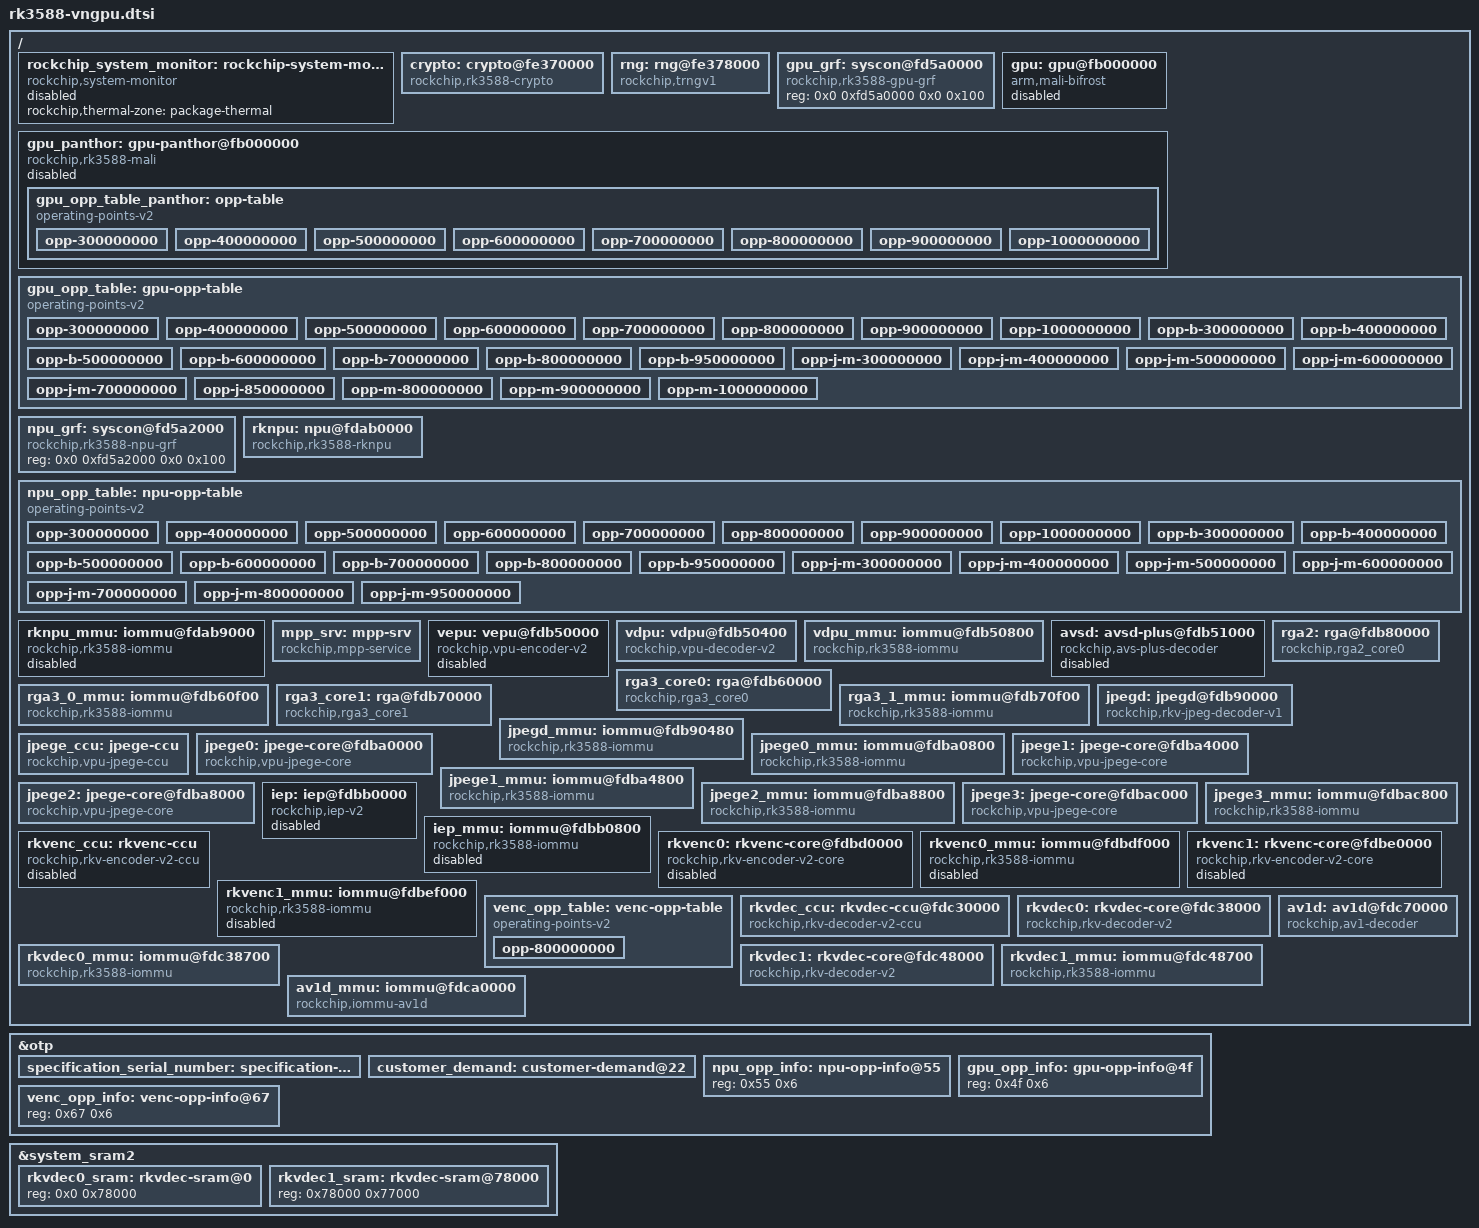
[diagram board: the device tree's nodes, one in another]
/*
 * Copyright (c) 2021 Rockchip Electronics Co., Ltd.
 * Copyright (c) 2025 jjm2473 <jjm2473@gmail.com>
 */

/delete-node/ &gpu;
/delete-node/ &gpu_opp_table;
/delete-node/ &av1d;

/{
	rockchip_system_monitor: rockchip-system-monitor {
		compatible = "rockchip,system-monitor";

		rockchip,thermal-zone = "package-thermal";
		status = "disabled";
	};

	crypto: crypto@fe370000 {
		compatible = "rockchip,rk3588-crypto";
		reg = <0x0 0xfe370000 0x0 0x2000>;
		interrupts = <GIC_SPI 209 IRQ_TYPE_LEVEL_HIGH 0>;
		clocks = <&scmi_clk SCMI_ACLK_SECURE_NS>, <&scmi_clk SCMI_HCLK_SECURE_NS>,
			 <&scmi_clk SCMI_CRYPTO_CORE>, <&scmi_clk SCMI_CRYPTO_PKA>;
		clock-names = "aclk", "hclk", "sclk", "pka";
		resets = <&scmi_reset SRST_CRYPTO_CORE>;
		reset-names = "crypto-rst";
		status = "disabled";
	};

	rng: rng@fe378000 {
		compatible = "rockchip,trngv1";
		reg = <0x0 0xfe378000 0x0 0x200>;
		interrupts = <GIC_SPI 400 IRQ_TYPE_LEVEL_HIGH 0>;
		clocks = <&scmi_clk SCMI_HCLK_SECURE_NS>;
		clock-names = "hclk_trng";
		resets = <&scmi_reset SRST_H_TRNG_NS>;
		reset-names = "reset";
		status = "disabled";
	};

	gpu_grf: syscon@fd5a0000 {
		compatible = "rockchip,rk3588-gpu-grf", "syscon";
		reg = <0x0 0xfd5a0000 0x0 0x100>;
	};

	gpu: gpu@fb000000 {
		compatible = "arm,mali-bifrost";
		reg = <0x0 0xfb000000 0x0 0x200000>;
		interrupts = <GIC_SPI 94 IRQ_TYPE_LEVEL_HIGH 0>,
			     <GIC_SPI 93 IRQ_TYPE_LEVEL_HIGH 0>,
			     <GIC_SPI 92 IRQ_TYPE_LEVEL_HIGH 0>;
		interrupt-names = "GPU", "MMU", "JOB";

		clocks = <&scmi_clk SCMI_CLK_GPU>, <&cru CLK_GPU_COREGROUP>,
			 <&cru CLK_GPU_STACKS>, <&cru CLK_GPU>;
		clock-names = "clk_mali", "clk_gpu_coregroup",
			      "clk_gpu_stacks", "clk_gpu";
		assigned-clocks = <&scmi_clk SCMI_CLK_GPU>;
		assigned-clock-rates = <200000000>;
		power-domains = <&power RK3588_PD_GPU>;
		operating-points-v2 = <&gpu_opp_table>;
		#cooling-cells = <2>;
		dynamic-power-coefficient = <2982>;

		upthreshold = <30>;
		downdifferential = <10>;

		status = "disabled";
	};

	gpu_panthor: gpu-panthor@fb000000 {
		compatible = "rockchip,rk3588-mali", "arm,mali-valhall-csf";
		reg = <0x0 0xfb000000 0x0 0x200000>;
		#cooling-cells = <2>;
		assigned-clocks = <&scmi_clk SCMI_CLK_GPU>;
		assigned-clock-rates = <200000000>;
		clocks = <&cru CLK_GPU>, <&cru CLK_GPU_COREGROUP>,
			 <&cru CLK_GPU_STACKS>;
		clock-names = "core", "coregroup", "stacks";
		dynamic-power-coefficient = <2982>;
		interrupts = <GIC_SPI 92 IRQ_TYPE_LEVEL_HIGH 0>,
			     <GIC_SPI 93 IRQ_TYPE_LEVEL_HIGH 0>,
			     <GIC_SPI 94 IRQ_TYPE_LEVEL_HIGH 0>;
		interrupt-names = "job", "mmu", "gpu";
		operating-points-v2 = <&gpu_opp_table_panthor>;
		power-domains = <&power RK3588_PD_GPU>;
		status = "disabled";

		gpu_opp_table_panthor: opp-table {
			compatible = "operating-points-v2";

			opp-300000000 {
				opp-hz = /bits/ 64 <300000000>;
				opp-microvolt = <675000 675000 850000>;
			};
			opp-400000000 {
				opp-hz = /bits/ 64 <400000000>;
				opp-microvolt = <675000 675000 850000>;
			};
			opp-500000000 {
				opp-hz = /bits/ 64 <500000000>;
				opp-microvolt = <675000 675000 850000>;
			};
			opp-600000000 {
				opp-hz = /bits/ 64 <600000000>;
				opp-microvolt = <675000 675000 850000>;
			};
			opp-700000000 {
				opp-hz = /bits/ 64 <700000000>;
				opp-microvolt = <700000 700000 850000>;
			};
			opp-800000000 {
				opp-hz = /bits/ 64 <800000000>;
				opp-microvolt = <750000 750000 850000>;
			};
			opp-900000000 {
				opp-hz = /bits/ 64 <900000000>;
				opp-microvolt = <800000 800000 850000>;
			};
			opp-1000000000 {
				opp-hz = /bits/ 64 <1000000000>;
				opp-microvolt = <850000 850000 850000>;
			};
		};
	};

	gpu_opp_table: gpu-opp-table {
		compatible = "operating-points-v2";

		nvmem-cells = <&gpu_leakage>, <&gpu_opp_info>,
			      <&specification_serial_number>, <&customer_demand>;
		nvmem-cell-names = "leakage", "opp-info",
				   "specification_serial_number", "customer_demand";
		rockchip,supported-hw;

		rockchip,pvtm-hw = <0x04>;
		rockchip,pvtm-voltage-sel-hw = <
			0	799	0
			800	819	1
			820	844	2
			845	869	3
			870	894	4
			895	9999	5
		>;
		rockchip,pvtm-voltage-sel-B4 = <
			0	755	0
			756	775	1
			776	795	2
			796	815	3
			816	835	4
			836	860	5
			861	885	6
			886	910	7
			911	9999	8
		>;
		rockchip,pvtm-voltage-sel = <
			0	815	0
			816	835	1
			836	860	2
			861	885	3
			886	910	4
			911	9999	5
		>;
		rockchip,pvtm-pvtpll;
		rockchip,pvtm-offset = <0x1c>;
		rockchip,pvtm-sample-time = <1100>;
		rockchip,pvtm-freq = <800000>;
		rockchip,pvtm-volt = <750000>;
		rockchip,pvtm-ref-temp = <25>;
		rockchip,pvtm-temp-prop = <(-135) (-135)>;
		rockchip,pvtm-thermal-zone = "gpu-thermal";

		rockchip,opp-clocks = <&cru CLK_GPU>;
		rockchip,grf = <&gpu_grf>;
		volt-mem-read-margin = <
			855000	1
			765000	2
			675000	3
			495000	4
		>;
		low-volt-mem-read-margin = <4>;
		intermediate-threshold-freq = <400000>;	/* KHz */

		rockchip,temp-hysteresis = <5000>;
		rockchip,low-temp = <15000>;
		rockchip,low-temp-min-volt = <750000>;
		rockchip,high-temp = <85000>;
		rockchip,high-temp-max-freq = <800000>;

		/* RK3588 gpu OPPs */
		opp-300000000 {
			opp-supported-hw = <0xe9 0xffff>;
			opp-hz = /bits/ 64 <300000000>;
			opp-microvolt = <675000 675000 850000>,
					<675000 675000 850000>;
		};
		opp-400000000 {
			opp-supported-hw = <0xe9 0xffff>;
			opp-hz = /bits/ 64 <400000000>;
			opp-microvolt = <675000 675000 850000>,
					<675000 675000 850000>;
		};
		opp-500000000 {
			opp-supported-hw = <0xe9 0xffff>;
			opp-hz = /bits/ 64 <500000000>;
			opp-microvolt = <675000 675000 850000>,
					<675000 675000 850000>;
		};
		opp-600000000 {
			opp-supported-hw = <0xe9 0xffff>;
			opp-hz = /bits/ 64 <600000000>;
			opp-microvolt = <675000 675000 850000>,
					<675000 675000 850000>;
		};
		opp-700000000 {
			opp-supported-hw = <0xe9 0xffff>;
			opp-hz = /bits/ 64 <700000000>;
			opp-microvolt = <700000 700000 850000>,
					<700000 700000 850000>;
			opp-microvolt-L2 = <687500 687500 850000>,
					   <687500 687500 850000>;
			opp-microvolt-L3 = <675000 675000 850000>,
					   <675000 675000 850000>;
			opp-microvolt-L4 = <675000 675000 850000>,
					   <675000 675000 850000>;
			opp-microvolt-L5 = <675000 675000 850000>,
					   <675000 675000 850000>;
		};
		opp-800000000 {
			opp-supported-hw = <0xe9 0xffff>;
			opp-hz = /bits/ 64 <800000000>;
			opp-microvolt = <750000 750000 850000>,
					<750000 750000 850000>;
			opp-microvolt-L1 = <737500 737500 850000>,
					   <737500 737500 850000>;
			opp-microvolt-L2 = <725000 725000 850000>,
					   <725000 725000 850000>;
			opp-microvolt-L3 = <712500 712500 850000>,
					   <712500 712500 850000>;
			opp-microvolt-L4 = <700000 700000 850000>,
					   <700000 700000 850000>;
			opp-microvolt-L5 = <700000 700000 850000>,
					   <700000 700000 850000>;
		};
		opp-900000000 {
			opp-supported-hw = <0xe9 0xffff>;
			opp-hz = /bits/ 64 <900000000>;
			opp-microvolt = <800000 800000 850000>,
					<800000 800000 850000>;
			opp-microvolt-L1 = <787500 787500 850000>,
					   <787500 787500 850000>;
			opp-microvolt-L2 = <775000 775000 850000>,
					   <775000 775000 850000>;
			opp-microvolt-L3 = <762500 762500 850000>,
					   <762500 762500 850000>;
			opp-microvolt-L4 = <750000 750000 850000>,
					   <750000 750000 850000>;
			opp-microvolt-L5 = <737500 737500 850000>,
					   <737500 737500 850000>;
		};
		opp-1000000000 {
			opp-supported-hw = <0xe9 0xffff>;
			opp-hz = /bits/ 64 <1000000000>;
			opp-microvolt = <850000 850000 850000>,
					<850000 850000 850000>;
			opp-microvolt-L1 = <837500 837500 850000>,
					   <837500 837500 850000>;
			opp-microvolt-L2 = <825000 825000 850000>,
					   <825000 825000 850000>;
			opp-microvolt-L3 = <812500 812500 850000>,
					   <812500 812500 850000>;
			opp-microvolt-L4 = <800000 800000 850000>,
					   <800000 800000 850000>;
			opp-microvolt-L5 = <787500 787500 850000>,
					   <787500 787500 850000>;
		};

		opp-b-300000000 {
			opp-supported-hw = <0x10 0xffff>;
			opp-hz = /bits/ 64 <300000000>;
			opp-microvolt = <675000 675000 850000>,
					<675000 675000 850000>;
			opp-microvolt-L0 = <712500 712500 850000>,
					   <712500 712500 850000>;
			opp-microvolt-L1 = <700000 700000 850000>,
					   <700000 700000 850000>;
			opp-microvolt-L2 = <687500 687500 850000>,
					   <687500 687500 850000>;
		};
		opp-b-400000000 {
			opp-supported-hw = <0x10 0xffff>;
			opp-hz = /bits/ 64 <400000000>;
			opp-microvolt = <675000 675000 850000>,
					<675000 675000 850000>;
			opp-microvolt-L0 = <712500 712500 850000>,
					   <712500 712500 850000>;
			opp-microvolt-L1 = <700000 700000 850000>,
					   <700000 700000 850000>;
			opp-microvolt-L2 = <687500 687500 850000>,
					   <687500 687500 850000>;
		};
		opp-b-500000000 {
			opp-supported-hw = <0x10 0xffff>;
			opp-hz = /bits/ 64 <500000000>;
			opp-microvolt = <675000 675000 850000>,
					<675000 675000 850000>;
			opp-microvolt-L0 = <712500 712500 850000>,
					   <712500 712500 850000>;
			opp-microvolt-L1 = <700000 700000 850000>,
					   <700000 700000 850000>;
			opp-microvolt-L2 = <687500 687500 850000>,
					   <687500 687500 850000>;
		};
		opp-b-600000000 {
			opp-supported-hw = <0x10 0xffff>;
			opp-hz = /bits/ 64 <600000000>;
			opp-microvolt = <675000 675000 850000>,
					<675000 675000 850000>;
			opp-microvolt-L0 = <712500 712500 850000>,
					   <712500 712500 850000>;
			opp-microvolt-L1 = <700000 700000 850000>,
					   <700000 700000 850000>;
			opp-microvolt-L2 = <687500 687500 850000>,
					   <687500 687500 850000>;
		};
		opp-b-700000000 {
			opp-supported-hw = <0x10 0xffff>;
			opp-hz = /bits/ 64 <700000000>;
			opp-microvolt-L0 = <737500 737500 850000>,
					   <737500 737500 850000>;
			opp-microvolt-L1 = <725000 725000 850000>,
					   <725000 725000 850000>;
			opp-microvolt-L2 = <712500 712500 850000>,
					   <712500 712500 850000>;
			opp-microvolt-L3 = <700000 700000 850000>,
					   <700000 700000 850000>;
			opp-microvolt-L4 = <700000 700000 850000>,
					   <700000 700000 850000>;
			opp-microvolt-L5 = <687500 687500 850000>,
					   <687500 687500 850000>;
			opp-microvolt-L6 = <675000 675000 850000>,
					   <675000 675000 850000>;
			opp-microvolt-L7 = <675000 675000 850000>,
					   <675000 675000 850000>;
			opp-microvolt-L8 = <675000 675000 850000>,
					   <675000 675000 850000>;
		};
		opp-b-800000000 {
			opp-supported-hw = <0x10 0xffff>;
			opp-hz = /bits/ 64 <800000000>;
			opp-microvolt-L0 = <787500 787500 850000>,
					   <787500 787500 850000>;
			opp-microvolt-L1 = <775000 775000 850000>,
					   <775000 775000 850000>;
			opp-microvolt-L2 = <762500 762500 850000>,
					   <762500 762500 850000>;
			opp-microvolt-L3 = <750000 750000 850000>,
					   <750000 750000 850000>;
			opp-microvolt-L4 = <737500 737500 850000>,
					   <737500 737500 850000>;
			opp-microvolt-L5 = <725000 725000 850000>,
					   <725000 725000 850000>;
			opp-microvolt-L6 = <712500 712500 850000>,
					   <712500 712500 850000>;
			opp-microvolt-L7 = <700000 700000 850000>,
					   <700000 700000 850000>;
			opp-microvolt-L8 = <700000 700000 850000>,
					   <700000 700000 850000>;
		};
		opp-b-950000000 {
			opp-supported-hw = <0x10 0xffff>;
			opp-hz = /bits/ 64 <950000000>;
			opp-microvolt = <850000 850000 850000>,
					<850000 850000 850000>;
			opp-microvolt-L2 = <837500 837500 850000>,
					   <837500 837500 850000>;
			opp-microvolt-L3 = <825000 825000 850000>,
					   <825000 825000 850000>;
			opp-microvolt-L4 = <812500 812500 850000>,
					   <812500 812500 850000>;
			opp-microvolt-L5 = <800000 800000 850000>,
					   <800000 800000 850000>;
			opp-microvolt-L6 = <787500 787500 850000>,
					   <787500 787500 850000>;
			opp-microvolt-L7 = <775000 775000 850000>,
					   <775000 775000 850000>;
			opp-microvolt-L8 = <762500 762500 850000>,
					   <762500 762500 850000>;
		};

		/* RK3588J/M gpu OPPs */
		opp-j-m-300000000 {
			opp-supported-hw = <0x06 0xffff>;
			opp-hz = /bits/ 64 <300000000>;
			opp-microvolt = <750000 750000 850000>,
					<750000 750000 850000>;
		};
		opp-j-m-400000000 {
			opp-supported-hw = <0x06 0xffff>;
			opp-hz = /bits/ 64 <400000000>;
			opp-microvolt = <750000 750000 850000>,
					<750000 750000 850000>;
		};
		opp-j-m-500000000 {
			opp-supported-hw = <0x06 0xffff>;
			opp-hz = /bits/ 64 <500000000>;
			opp-microvolt = <750000 750000 850000>,
					<750000 750000 850000>;
		};
		opp-j-m-600000000 {
			opp-supported-hw = <0x06 0xffff>;
			opp-hz = /bits/ 64 <600000000>;
			opp-microvolt = <750000 750000 850000>,
					<750000 750000 850000>;
		};
		opp-j-m-700000000 {
			opp-supported-hw = <0x06 0xffff>;
			opp-hz = /bits/ 64 <700000000>;
			opp-microvolt = <750000 750000 850000>,
					<750000 750000 850000>;
		};
		/* RK3588J gpu OPPs */
		opp-j-850000000 {
			opp-supported-hw = <0x04 0xffff>;
			opp-hz = /bits/ 64 <850000000>;
			opp-microvolt = <787500 787500 850000>,
					<787500 787500 850000>;
			opp-microvolt-L1 = <775000 775000 850000>,
					   <775000 775000 850000>;
			opp-microvolt-L2 = <762500 762500 850000>,
					   <762500 762500 850000>;
			opp-microvolt-L3 = <750000 750000 850000>,
					   <750000 750000 850000>;
			opp-microvolt-L4 = <750000 750000 850000>,
					   <750000 750000 850000>;
			opp-microvolt-L5 = <750000 750000 850000>,
					   <750000 750000 850000>;
		};
		/* RK3588M gpu OPPs */
		opp-m-800000000 {
			opp-supported-hw = <0x02 0xffff>;
			opp-hz = /bits/ 64 <800000000>;
			opp-microvolt = <750000 750000 850000>,
					<750000 750000 850000>;
		};
		opp-m-900000000 {
			opp-supported-hw = <0x02 0xffff>;
			opp-hz = /bits/ 64 <900000000>;
			opp-microvolt = <800000 800000 850000>,
					<800000 800000 850000>;
			opp-microvolt-L1 = <787500 787500 850000>,
					   <787500 787500 850000>;
			opp-microvolt-L2 = <775000 775000 850000>,
					   <775000 775000 850000>;
			opp-microvolt-L3 = <762500 762500 850000>,
					   <762500 762500 850000>;
			opp-microvolt-L4 = <750000 750000 850000>,
					   <750000 750000 850000>;
			opp-microvolt-L5 = <750000 750000 850000>,
					   <750000 750000 850000>;
		};
		opp-m-1000000000 {
			opp-supported-hw = <0x02 0xffff>;
			opp-hz = /bits/ 64 <1000000000>;
			opp-microvolt = <850000 850000 850000>,
					<850000 850000 850000>;
			opp-microvolt-L1 = <837500 837500 850000>,
					   <837500 837500 850000>;
			opp-microvolt-L2 = <825000 825000 850000>,
					   <825000 825000 850000>;
			opp-microvolt-L3 = <812500 812500 850000>,
					   <812500 812500 850000>;
			opp-microvolt-L4 = <800000 800000 850000>,
					   <800000 800000 850000>;
			opp-microvolt-L5 = <787500 787500 850000>,
					   <787500 787500 850000>;
		};
	};

	npu_grf: syscon@fd5a2000 {
		compatible = "rockchip,rk3588-npu-grf", "syscon";
		reg = <0x0 0xfd5a2000 0x0 0x100>;
	};

	rknpu: npu@fdab0000 {
		compatible = "rockchip,rk3588-rknpu";
		reg = <0x0 0xfdab0000 0x0 0x10000>,
		      <0x0 0xfdac0000 0x0 0x10000>,
		      <0x0 0xfdad0000 0x0 0x10000>;
		interrupts = <GIC_SPI 110 IRQ_TYPE_LEVEL_HIGH 0>,
			     <GIC_SPI 111 IRQ_TYPE_LEVEL_HIGH 0>,
			     <GIC_SPI 112 IRQ_TYPE_LEVEL_HIGH 0>;
		interrupt-names = "npu0_irq", "npu1_irq", "npu2_irq";
		clocks = <&scmi_clk SCMI_CLK_NPU>, <&cru ACLK_NPU0>,
			 <&cru ACLK_NPU1>, <&cru ACLK_NPU2>,
			 <&cru HCLK_NPU0>, <&cru HCLK_NPU1>,
			 <&cru HCLK_NPU2>, <&cru PCLK_NPU_ROOT>;
		clock-names = "clk_npu", "aclk0",
			      "aclk1", "aclk2",
			      "hclk0", "hclk1",
			      "hclk2", "pclk";
		assigned-clocks = <&scmi_clk SCMI_CLK_NPU>;
		assigned-clock-rates = <200000000>;
		resets = <&cru SRST_A_RKNN0>, <&cru SRST_A_RKNN1>, <&cru SRST_A_RKNN2>,
			 <&cru SRST_H_RKNN0>, <&cru SRST_H_RKNN1>, <&cru SRST_H_RKNN2>;
		reset-names = "srst_a0", "srst_a1", "srst_a2",
			      "srst_h0", "srst_h1", "srst_h2";
		power-domains = <&power RK3588_PD_NPUTOP>,
				<&power RK3588_PD_NPU1>,
				<&power RK3588_PD_NPU2>;
		power-domain-names = "npu0", "npu1", "npu2";
		operating-points-v2 = <&npu_opp_table>;
		iommus = <&rknpu_mmu>;
		status = "disabled";
	};

	npu_opp_table: npu-opp-table {
		compatible = "operating-points-v2";

		nvmem-cells = <&npu_leakage>, <&npu_opp_info>,
			      <&specification_serial_number>, <&customer_demand>;
		nvmem-cell-names = "leakage", "opp-info",
				   "specification_serial_number", "customer_demand";
		rockchip,supported-hw;

		rockchip,pvtm-hw = <0x06>;
		rockchip,pvtm-voltage-sel-hw = <
			0	799	0
			800	819	1
			820	844	2
			845	869	3
			870	894	4
			895	9999	5
		>;
		rockchip,pvtm-voltage-sel-B4 = <
			0	755	0
			756	775	1
			776	795	2
			796	815	3
			816	835	4
			836	860	5
			861	885	6
			886	910	7
			911	9999	8
		>;
		rockchip,pvtm-voltage-sel = <
			0	815	0
			816	835	1
			836	860	2
			861	885	3
			886	910	4
			911	9999	5
		>;
		rockchip,pvtm-pvtpll;
		rockchip,pvtm-offset = <0x50>;
		rockchip,pvtm-sample-time = <1100>;
		rockchip,pvtm-freq = <800000>;
		rockchip,pvtm-volt = <750000>;
		rockchip,pvtm-ref-temp = <25>;
		rockchip,pvtm-temp-prop = <(-113) (-113)>;
		rockchip,pvtm-thermal-zone = "npu-thermal";

		rockchip,opp-clocks = <&cru PCLK_NPU_GRF>, <&cru HCLK_NPU_ROOT>;
		rockchip,grf = <&npu_grf>;
		volt-mem-read-margin = <
			855000	1
			765000	2
			675000	3
			495000	4
		>;
		low-volt-mem-read-margin = <4>;
		intermediate-threshold-freq = <500000>;	/* KHz*/
		rockchip,init-freq = <1000000>;		/* KHz */

		rockchip,temp-hysteresis = <5000>;
		rockchip,low-temp = <15000>;
		rockchip,low-temp-min-volt = <750000>;
		rockchip,high-temp = <85000>;
		rockchip,high-temp-max-freq = <800000>;

		/* RK3588 npu OPPs */
		opp-300000000 {
			opp-supported-hw = <0xe9 0xffff>;
			opp-hz = /bits/ 64 <300000000>;
			opp-microvolt = <700000 700000 850000>,
					<700000 700000 850000>;
			opp-microvolt-L1 = <687500 687500 850000>,
					   <687500 687500 850000>;
			opp-microvolt-L2 = <675000 675000 850000>,
					   <675000 675000 850000>;
			opp-microvolt-L3 = <675000 675000 850000>,
					   <675000 675000 850000>;
			opp-microvolt-L4 = <675000 675000 850000>,
					   <675000 675000 850000>;
			opp-microvolt-L5 = <675000 675000 850000>,
					   <675000 675000 850000>;
		};
		opp-400000000 {
			opp-supported-hw = <0xe9 0xffff>;
			opp-hz = /bits/ 64 <400000000>;
			opp-microvolt = <700000 700000 850000>,
					<700000 700000 850000>;
			opp-microvolt-L1 = <687500 687500 850000>,
					   <687500 687500 850000>;
			opp-microvolt-L2 = <675000 675000 850000>,
					   <675000 675000 850000>;
			opp-microvolt-L3 = <675000 675000 850000>,
					   <675000 675000 850000>;
			opp-microvolt-L4 = <675000 675000 850000>,
					   <675000 675000 850000>;
			opp-microvolt-L5 = <675000 675000 850000>,
					   <675000 675000 850000>;
		};
		opp-500000000 {
			opp-supported-hw = <0xe9 0xffff>;
			opp-hz = /bits/ 64 <500000000>;
			opp-microvolt = <700000 700000 850000>,
					<700000 700000 850000>;
			opp-microvolt-L1 = <687500 687500 850000>,
					   <687500 687500 850000>;
			opp-microvolt-L2 = <675000 675000 850000>,
					   <675000 675000 850000>;
			opp-microvolt-L3 = <675000 675000 850000>,
					   <675000 675000 850000>;
			opp-microvolt-L4 = <675000 675000 850000>,
					   <675000 675000 850000>;
			opp-microvolt-L5 = <675000 675000 850000>,
					   <675000 675000 850000>;
		};
		opp-600000000 {
			opp-supported-hw = <0xe9 0xffff>;
			opp-hz = /bits/ 64 <600000000>;
			opp-microvolt = <700000 700000 850000>,
					<700000 700000 850000>;
			opp-microvolt-L1 = <687500 687500 850000>,
					   <687500 687500 850000>;
			opp-microvolt-L2 = <675000 675000 850000>,
					   <675000 675000 850000>;
			opp-microvolt-L3 = <675000 675000 850000>,
					   <675000 675000 850000>;
			opp-microvolt-L4 = <675000 675000 850000>,
					   <675000 675000 850000>;
			opp-microvolt-L5 = <675000 675000 850000>,
					   <675000 675000 850000>;
		};
		opp-700000000 {
			opp-supported-hw = <0xe9 0xffff>;
			opp-hz = /bits/ 64 <700000000>;
			opp-microvolt = <700000 700000 850000>,
					<700000 700000 850000>;
			opp-microvolt-L3 = <687500 687500 850000>,
					   <687500 687500 850000>;
			opp-microvolt-L4 = <675000 675000 850000>,
					   <675000 675000 850000>;
			opp-microvolt-L5 = <675000 675000 850000>,
					   <675000 675000 850000>;
		};
		opp-800000000 {
			opp-supported-hw = <0xe9 0xffff>;
			opp-hz = /bits/ 64 <800000000>;
			opp-microvolt = <750000 750000 850000>,
					<750000 750000 850000>;
			opp-microvolt-L2 = <737500 737500 850000>,
					   <737500 737500 850000>;
			opp-microvolt-L3 = <725000 725000 850000>,
					   <725000 725000 850000>;
			opp-microvolt-L4 = <712500 712500 850000>,
					   <712500 712500 850000>;
			opp-microvolt-L5 = <700000 700000 850000>,
					   <700000 700000 850000>;
		};
		opp-900000000 {
			opp-supported-hw = <0xe9 0xffff>;
			opp-hz = /bits/ 64 <900000000>;
			opp-microvolt = <800000 800000 850000>,
					<800000 800000 850000>;
			opp-microvolt-L1 = <787500 787500 850000>,
					   <787500 787500 850000>;
			opp-microvolt-L2 = <775000 775000 850000>,
					   <775000 775000 850000>;
			opp-microvolt-L3 = <762500 762500 850000>,
					   <762500 762500 850000>;
			opp-microvolt-L4 = <750000 750000 850000>,
					   <750000 750000 850000>;
			opp-microvolt-L5 = <737500 737500 850000>,
					   <737500 737500 850000>;
		};
		opp-1000000000 {
			opp-supported-hw = <0xe9 0xffff>;
			opp-hz = /bits/ 64 <1000000000>;
			opp-microvolt = <850000 850000 850000>,
					<850000 850000 850000>;
			opp-microvolt-L1 = <837500 837500 850000>,
					   <837500 837500 850000>;
			opp-microvolt-L2 = <825000 825000 850000>,
					   <825000 825000 850000>;
			opp-microvolt-L3 = <812500 812500 850000>,
					   <812500 812500 850000>;
			opp-microvolt-L4 = <800000 800000 850000>,
					   <800000 800000 850000>;
			opp-microvolt-L5 = <787500 787500 850000>,
					   <787500 787500 850000>;
		};

		opp-b-300000000 {
			opp-supported-hw = <0x10 0xffff>;
			opp-hz = /bits/ 64 <300000000>;
			opp-microvolt = <675000 675000 850000>,
					<675000 675000 850000>;
			opp-microvolt-L0 = <725000 725000 850000>,
					   <725000 725000 850000>;
			opp-microvolt-L1 = <712500 712500 850000>,
					   <712500 712500 850000>;
			opp-microvolt-L2 = <712500 712500 850000>,
					   <712500 712500 850000>;
			opp-microvolt-L3 = <700000 700000 850000>,
					   <700000 700000 850000>;
			opp-microvolt-L4 = <687500 687500 850000>,
					   <687500 687500 850000>;
		};
		opp-b-400000000 {
			opp-supported-hw = <0x10 0xffff>;
			opp-hz = /bits/ 64 <400000000>;
			opp-microvolt = <675000 675000 850000>,
					<675000 675000 850000>;
			opp-microvolt-L0 = <725000 725000 850000>,
					   <725000 725000 850000>;
			opp-microvolt-L1 = <712500 712500 850000>,
					   <712500 712500 850000>;
			opp-microvolt-L2 = <712500 712500 850000>,
					   <712500 712500 850000>;
			opp-microvolt-L3 = <700000 700000 850000>,
					   <700000 700000 850000>;
			opp-microvolt-L4 = <687500 687500 850000>,
					   <687500 687500 850000>;
		};
		opp-b-500000000 {
			opp-supported-hw = <0x10 0xffff>;
			opp-hz = /bits/ 64 <500000000>;
			opp-microvolt = <675000 675000 850000>,
					<675000 675000 850000>;
			opp-microvolt-L0 = <725000 725000 850000>,
					   <725000 725000 850000>;
			opp-microvolt-L1 = <712500 712500 850000>,
					   <712500 712500 850000>;
			opp-microvolt-L2 = <712500 712500 850000>,
					   <712500 712500 850000>;
			opp-microvolt-L3 = <700000 700000 850000>,
					   <700000 700000 850000>;
			opp-microvolt-L4 = <687500 687500 850000>,
					   <687500 687500 850000>;
		};
		opp-b-600000000 {
			opp-supported-hw = <0x10 0xffff>;
			opp-hz = /bits/ 64 <600000000>;
			opp-microvolt = <675000 675000 850000>,
					<675000 675000 850000>;
			opp-microvolt-L0 = <725000 725000 850000>,
					   <725000 725000 850000>;
			opp-microvolt-L1 = <712500 712500 850000>,
					   <712500 712500 850000>;
			opp-microvolt-L2 = <712500 712500 850000>,
					   <712500 712500 850000>;
			opp-microvolt-L3 = <700000 700000 850000>,
					   <700000 700000 850000>;
			opp-microvolt-L4 = <687500 687500 850000>,
					   <687500 687500 850000>;
		};
		opp-b-700000000 {
			opp-supported-hw = <0x10 0xffff>;
			opp-hz = /bits/ 64 <700000000>;
			opp-microvolt = <737500 737500 850000>,
					<737500 737500 850000>;
			opp-microvolt-L1 = <725000 725000 850000>,
					   <725000 725000 850000>;
			opp-microvolt-L2 = <712500 712500 850000>,
					   <712500 712500 850000>;
			opp-microvolt-L3 = <700000 700000 850000>,
					   <700000 700000 850000>;
			opp-microvolt-L4 = <700000 700000 850000>,
					   <700000 700000 850000>;
			opp-microvolt-L5 = <687500 687500 850000>,
					   <687500 687500 850000>;
			opp-microvolt-L6 = <687500 687500 850000>,
					   <687500 687500 850000>;
			opp-microvolt-L7 = <675000 675000 850000>,
					   <675000 675000 850000>;
			opp-microvolt-L8 = <675000 675000 850000>,
					   <675000 675000 850000>;
		};
		opp-b-800000000 {
			opp-supported-hw = <0x10 0xffff>;
			opp-hz = /bits/ 64 <800000000>;
			opp-microvolt = <787500 787500 850000>,
					<787500 787500 850000>;
			opp-microvolt-L1 = <775000 775000 850000>,
					   <775000 775000 850000>;
			opp-microvolt-L2 = <762500 762500 850000>,
					   <762500 762500 850000>;
			opp-microvolt-L3 = <750000 750000 850000>,
					   <750000 750000 850000>;
			opp-microvolt-L4 = <750000 750000 850000>,
					   <750000 750000 850000>;
			opp-microvolt-L5 = <737500 737500 850000>,
					   <737500 737500 850000>;
			opp-microvolt-L6 = <725000 725000 850000>,
					   <725000 725000 850000>;
			opp-microvolt-L7 = <712500 712500 850000>,
					   <712500 712500 850000>;
			opp-microvolt-L8 = <700000 700000 850000>,
					   <700000 700000 850000>;
		};
		opp-b-950000000 {
			opp-supported-hw = <0x10 0xffff>;
			opp-hz = /bits/ 64 <950000000>;
			opp-microvolt = <850000 850000 850000>,
					<850000 850000 850000>;
			opp-microvolt-L2 = <850000 850000 850000>,
					   <850000 850000 850000>;
			opp-microvolt-L3 = <837500 837500 850000>,
					   <837500 837500 850000>;
			opp-microvolt-L4 = <825000 825000 850000>,
					   <825000 825000 850000>;
			opp-microvolt-L5 = <812500 812500 850000>,
					   <812500 812500 850000>;
			opp-microvolt-L6 = <800000 800000 850000>,
					   <800000 800000 850000>;
			opp-microvolt-L7 = <787500 787500 850000>,
					   <787500 787500 850000>;
			opp-microvolt-L8 = <775000 775000 850000>,
					   <775000 775000 850000>;
		};

		/* RK3588J/M npu OPPs */
		opp-j-m-300000000 {
			opp-supported-hw = <0x06 0xffff>;
			opp-hz = /bits/ 64 <300000000>;
			opp-microvolt = <750000 750000 850000>,
					<750000 750000 850000>;
		};
		opp-j-m-400000000 {
			opp-supported-hw = <0x06 0xffff>;
			opp-hz = /bits/ 64 <400000000>;
			opp-microvolt = <750000 750000 850000>,
					<750000 750000 850000>;
		};
		opp-j-m-500000000 {
			opp-supported-hw = <0x06 0xffff>;
			opp-hz = /bits/ 64 <500000000>;
			opp-microvolt = <750000 750000 850000>,
					<750000 750000 850000>;
		};
		opp-j-m-600000000 {
			opp-supported-hw = <0x06 0xffff>;
			opp-hz = /bits/ 64 <600000000>;
			opp-microvolt = <750000 750000 850000>,
					<750000 750000 850000>;
		};
		opp-j-m-700000000 {
			opp-supported-hw = <0x06 0xffff>;
			opp-hz = /bits/ 64 <700000000>;
			opp-microvolt = <750000 750000 850000>,
					<750000 750000 850000>;
		};
		opp-j-m-800000000 {
			opp-supported-hw = <0x06 0xffff>;
			opp-hz = /bits/ 64 <800000000>;
			opp-microvolt = <750000 750000 850000>,
					<750000 750000 850000>;
		};
		opp-j-m-950000000 {
			opp-supported-hw = <0x06 0xffff>;
			opp-hz = /bits/ 64 <950000000>;
			opp-microvolt = <837500 837500 850000>,
					<837500 837500 850000>;
			opp-microvolt-L1 = <825000 825000 850000>,
					   <825000 825000 850000>;
			opp-microvolt-L2 = <812500 812500 850000>,
					   <812500 812500 850000>;
			opp-microvolt-L3 = <800000 800000 850000>,
					   <800000 800000 850000>;
			opp-microvolt-L4 = <787500 787500 850000>,
					   <787500 787500 850000>;
			opp-microvolt-L5 = <775000 775000 850000>,
					   <775000 775000 850000>;
		};
	};

	rknpu_mmu: iommu@fdab9000 {
		compatible = "rockchip,rk3588-iommu", "rockchip,rk3568-iommu", "rockchip,iommu-v2";
		reg = <0x0 0xfdab9000 0x0 0x100>,
		      <0x0 0xfdaba000 0x0 0x100>,
		      <0x0 0xfdaca000 0x0 0x100>,
		      <0x0 0xfdada000 0x0 0x100>;
		interrupts = <GIC_SPI 110 IRQ_TYPE_LEVEL_HIGH 0>,
			     <GIC_SPI 111 IRQ_TYPE_LEVEL_HIGH 0>,
			     <GIC_SPI 112 IRQ_TYPE_LEVEL_HIGH 0>;
		interrupt-names = "npu0_mmu", "npu1_mmu", "npu2_mmu";
		clocks = <&cru ACLK_NPU0>, <&cru ACLK_NPU1>, <&cru ACLK_NPU2>,
			 <&cru HCLK_NPU0>, <&cru HCLK_NPU1>, <&cru HCLK_NPU2>;
		clock-names = "aclk0", "aclk1", "aclk2",
			      "iface0", "iface1", "iface2";
		#iommu-cells = <0>;
		status = "disabled";
	};
	
	mpp_srv: mpp-srv {
		compatible = "rockchip,mpp-service";
		rockchip,taskqueue-count = <12>;
		rockchip,resetgroup-count = <1>;
		status = "disabled";
	};

	vepu: vepu@fdb50000 {
		compatible = "rockchip,vpu-encoder-v2";
		reg = <0x0 0xfdb50000 0x0 0x400>;
		interrupts = <GIC_SPI 120 IRQ_TYPE_LEVEL_HIGH 0>;
		interrupt-names = "irq_vepu";
		clocks = <&cru ACLK_VPU>, <&cru HCLK_VPU>;
		clock-names = "aclk_vcodec", "hclk_vcodec";
		rockchip,normal-rates = <594000000>, <0>;
		assigned-clocks = <&cru ACLK_VPU>;
		assigned-clock-rates = <594000000>;
		resets = <&cru SRST_A_VPU>, <&cru SRST_H_VPU>;
		reset-names = "shared_video_a", "shared_video_h";
		rockchip,skip-pmu-idle-request;
		rockchip,disable-auto-freq;
		iommus = <&vdpu_mmu>;
		rockchip,srv = <&mpp_srv>;
		rockchip,taskqueue-node = <0>;
		rockchip,resetgroup-node = <0>;
		power-domains = <&power RK3588_PD_VDPU>;
		status = "disabled";
	};

	vdpu: vdpu@fdb50400 {
		compatible = "rockchip,vpu-decoder-v2";
		reg = <0x0 0xfdb50400 0x0 0x400>;
		interrupts = <GIC_SPI 119 IRQ_TYPE_LEVEL_HIGH 0>;
		interrupt-names = "irq_vdpu";
		clocks = <&cru ACLK_VPU>, <&cru HCLK_VPU>;
		clock-names = "aclk_vcodec", "hclk_vcodec";
		rockchip,normal-rates = <594000000>, <0>;
		assigned-clocks = <&cru ACLK_VPU>;
		assigned-clock-rates = <594000000>;
		resets = <&cru SRST_A_VPU>, <&cru SRST_H_VPU>;
		reset-names = "shared_video_a", "shared_video_h";
		rockchip,skip-pmu-idle-request;
		rockchip,disable-auto-freq;
		iommus = <&vdpu_mmu>;
		rockchip,srv = <&mpp_srv>;
		rockchip,taskqueue-node = <0>;
		rockchip,resetgroup-node = <0>;
		power-domains = <&power RK3588_PD_VDPU>;
		status = "disabled";
	};

	vdpu_mmu: iommu@fdb50800 {
		compatible = "rockchip,rk3588-iommu", "rockchip,rk3568-iommu", "rockchip,iommu-v2";
		reg = <0x0 0xfdb50800 0x0 0x40>;
		interrupts = <GIC_SPI 118 IRQ_TYPE_LEVEL_HIGH 0>;
		interrupt-names = "irq_vdpu_mmu";
		clocks = <&cru ACLK_VPU>, <&cru HCLK_VPU>;
		clock-names = "aclk", "iface";
		power-domains = <&power RK3588_PD_VDPU>;
		#iommu-cells = <0>;
		status = "disabled";
	};

	avsd: avsd-plus@fdb51000 {
		compatible = "rockchip,avs-plus-decoder";
		reg = <0x0 0xfdb51000 0x0 0x200>;
		interrupts = <GIC_SPI 119 IRQ_TYPE_LEVEL_HIGH 0>;
		interrupt-names = "irq_avsd";
		clocks = <&cru ACLK_VPU>, <&cru HCLK_VPU>;
		clock-names = "aclk_vcodec", "hclk_vcodec";
		rockchip,normal-rates = <594000000>, <0>;
		assigned-clocks = <&cru ACLK_VPU>;
		assigned-clock-rates = <594000000>;
		resets = <&cru SRST_A_VPU>, <&cru SRST_H_VPU>;
		reset-names = "shared_video_a", "shared_video_h";
		rockchip,skip-pmu-idle-request;
		rockchip,disable-auto-freq;
		iommus = <&vdpu_mmu>;
		power-domains = <&power RK3588_PD_VDPU>;
		rockchip,srv = <&mpp_srv>;
		rockchip,taskqueue-node = <0>;
		rockchip,resetgroup-node = <0>;
		status = "disabled";
	};

	rga3_core0: rga@fdb60000 {
		compatible = "rockchip,rga3_core0";
		reg = <0x0 0xfdb60000 0x0 0x1000>;
		interrupts = <GIC_SPI 114 IRQ_TYPE_LEVEL_HIGH 0>;
		interrupt-names = "rga3_core0_irq";
		clocks = <&cru ACLK_RGA3_0>, <&cru HCLK_RGA3_0>, <&cru CLK_RGA3_0_CORE>;
		clock-names = "aclk_rga3_0", "hclk_rga3_0", "clk_rga3_0";
		power-domains = <&power RK3588_PD_RGA30>;
		iommus = <&rga3_0_mmu>;
		status = "disabled";
	};

	rga3_0_mmu: iommu@fdb60f00 {
		compatible = "rockchip,rk3588-iommu", "rockchip,rk3568-iommu", "rockchip,iommu-v2";
		reg = <0x0 0xfdb60f00 0x0 0x100>;
		interrupts = <GIC_SPI 114 IRQ_TYPE_LEVEL_HIGH 0>;
		interrupt-names = "rga3_0_mmu";
		clocks = <&cru ACLK_RGA3_0>, <&cru HCLK_RGA3_0>;
		clock-names = "aclk", "iface";
		power-domains = <&power RK3588_PD_RGA30>;
		#iommu-cells = <0>;
		status = "disabled";
	};

	rga3_core1: rga@fdb70000 {
		compatible = "rockchip,rga3_core1";
		reg = <0x0 0xfdb70000 0x0 0x1000>;
		interrupts = <GIC_SPI 115 IRQ_TYPE_LEVEL_HIGH 0>;
		interrupt-names = "rga3_core1_irq";
		clocks = <&cru ACLK_RGA3_1>, <&cru HCLK_RGA3_1>, <&cru CLK_RGA3_1_CORE>;
		clock-names = "aclk_rga3_1", "hclk_rga3_1", "clk_rga3_1";
		power-domains = <&power RK3588_PD_RGA31>;
		iommus = <&rga3_1_mmu>;
		status = "disabled";
	};

	rga3_1_mmu: iommu@fdb70f00 {
		compatible = "rockchip,rk3588-iommu", "rockchip,rk3568-iommu", "rockchip,iommu-v2";
		reg = <0x0 0xfdb70f00 0x0 0x100>;
		interrupts = <GIC_SPI 115 IRQ_TYPE_LEVEL_HIGH 0>;
		interrupt-names = "rga3_1_mmu";
		clocks = <&cru ACLK_RGA3_1>, <&cru HCLK_RGA3_1>;
		clock-names = "aclk", "iface";
		power-domains = <&power RK3588_PD_RGA31>;
		#iommu-cells = <0>;
		status = "disabled";
	};

	rga2: rga@fdb80000 {
		compatible = "rockchip,rga2_core0";
		reg = <0x0 0xfdb80000 0x0 0x1000>;
		interrupts = <GIC_SPI 116 IRQ_TYPE_LEVEL_HIGH 0>;
		interrupt-names = "rga2_irq";
		clocks = <&cru ACLK_RGA2>, <&cru HCLK_RGA2>, <&cru CLK_RGA2_CORE>;
		clock-names = "aclk_rga2", "hclk_rga2", "clk_rga2";
		power-domains = <&power RK3588_PD_VDPU>;
		status = "disabled";
	};

	jpegd: jpegd@fdb90000 {
		compatible = "rockchip,rkv-jpeg-decoder-v1";
		reg = <0x0 0xfdb90000 0x0 0x400>;
		interrupts = <GIC_SPI 129 IRQ_TYPE_LEVEL_HIGH 0>;
		interrupt-names = "irq_jpegd";
		clocks = <&cru ACLK_JPEG_DECODER>, <&cru HCLK_JPEG_DECODER>;
		clock-names = "aclk_vcodec", "hclk_vcodec";
		rockchip,normal-rates = <600000000>, <0>;
		assigned-clocks = <&cru ACLK_JPEG_DECODER>;
		assigned-clock-rates = <600000000>;
		resets = <&cru SRST_A_JPEG_DECODER>, <&cru SRST_H_JPEG_DECODER>;
		reset-names = "video_a", "video_h";
		rockchip,skip-pmu-idle-request;
		iommus = <&jpegd_mmu>;
		rockchip,srv = <&mpp_srv>;
		rockchip,taskqueue-node = <1>;
		power-domains = <&power RK3588_PD_VDPU>;
		status = "disabled";
	};

	jpegd_mmu: iommu@fdb90480 {
		compatible = "rockchip,rk3588-iommu", "rockchip,rk3568-iommu", "rockchip,iommu-v2";
		reg = <0x0 0xfdb90480 0x0 0x40>;
		interrupts = <GIC_SPI 130 IRQ_TYPE_LEVEL_HIGH 0>;
		interrupt-names = "irq_jpegd_mmu";
		clocks = <&cru ACLK_JPEG_DECODER>, <&cru HCLK_JPEG_DECODER>;
		clock-names = "aclk", "iface";
		power-domains = <&power RK3588_PD_VDPU>;
		#iommu-cells = <0>;
		status = "disabled";
	};

	jpege_ccu: jpege-ccu {
		compatible = "rockchip,vpu-jpege-ccu";
		status = "disabled";
	};

	jpege0: jpege-core@fdba0000 {
		compatible = "rockchip,vpu-jpege-core";
		reg = <0x0 0xfdba0000 0x0 0x400>;
		interrupts = <GIC_SPI 122 IRQ_TYPE_LEVEL_HIGH 0>;
		interrupt-names = "irq_jpege0";
		clocks = <&cru ACLK_JPEG_ENCODER0>, <&cru HCLK_JPEG_ENCODER0>;
		clock-names = "aclk_vcodec", "hclk_vcodec";
		rockchip,normal-rates = <594000000>, <0>;
		assigned-clocks = <&cru ACLK_JPEG_ENCODER0>;
		assigned-clock-rates = <594000000>;
		resets = <&cru SRST_A_JPEG_ENCODER0>, <&cru SRST_H_JPEG_ENCODER0>;
		reset-names = "video_a", "video_h";
		rockchip,skip-pmu-idle-request;
		rockchip,disable-auto-freq;
		iommus = <&jpege0_mmu>;
		rockchip,srv = <&mpp_srv>;
		rockchip,taskqueue-node = <2>;
		rockchip,ccu = <&jpege_ccu>;
		power-domains = <&power RK3588_PD_VDPU>;
		status = "disabled";
	};

	jpege0_mmu: iommu@fdba0800 {
		compatible = "rockchip,rk3588-iommu", "rockchip,rk3568-iommu", "rockchip,iommu-v2";
		reg = <0x0 0xfdba0800 0x0 0x40>;
		interrupts = <GIC_SPI 121 IRQ_TYPE_LEVEL_HIGH 0>;
		interrupt-names = "irq_jpege0_mmu";
		clocks = <&cru ACLK_JPEG_ENCODER0>, <&cru HCLK_JPEG_ENCODER0>;
		clock-names = "aclk", "iface";
		power-domains = <&power RK3588_PD_VDPU>;
		#iommu-cells = <0>;
		status = "disabled";
	};

	jpege1: jpege-core@fdba4000 {
		compatible = "rockchip,vpu-jpege-core";
		reg = <0x0 0xfdba4000 0x0 0x400>;
		interrupts = <GIC_SPI 124 IRQ_TYPE_LEVEL_HIGH 0>;
		interrupt-names = "irq_jpege1";
		clocks = <&cru ACLK_JPEG_ENCODER1>, <&cru HCLK_JPEG_ENCODER1>;
		clock-names = "aclk_vcodec", "hclk_vcodec";
		rockchip,normal-rates = <594000000>, <0>;
		assigned-clocks = <&cru ACLK_JPEG_ENCODER1>;
		assigned-clock-rates = <594000000>;
		resets = <&cru SRST_A_JPEG_ENCODER1>, <&cru SRST_H_JPEG_ENCODER1>;
		reset-names = "video_a", "video_h";
		rockchip,skip-pmu-idle-request;
		rockchip,disable-auto-freq;
		iommus = <&jpege1_mmu>;
		rockchip,srv = <&mpp_srv>;
		rockchip,taskqueue-node = <2>;
		rockchip,ccu = <&jpege_ccu>;
		power-domains = <&power RK3588_PD_VDPU>;
		status = "disabled";
	};

	jpege1_mmu: iommu@fdba4800 {
		compatible = "rockchip,rk3588-iommu", "rockchip,rk3568-iommu", "rockchip,iommu-v2";
		reg = <0x0 0xfdba4800 0x0 0x40>;
		interrupts = <GIC_SPI 123 IRQ_TYPE_LEVEL_HIGH 0>;
		interrupt-names = "irq_jpege1_mmu";
		clocks = <&cru ACLK_JPEG_ENCODER1>, <&cru HCLK_JPEG_ENCODER1>;
		clock-names = "aclk", "iface";
		power-domains = <&power RK3588_PD_VDPU>;
		#iommu-cells = <0>;
		status = "disabled";
	};

	jpege2: jpege-core@fdba8000 {
		compatible = "rockchip,vpu-jpege-core";
		reg = <0x0 0xfdba8000 0x0 0x400>;
		interrupts = <GIC_SPI 126 IRQ_TYPE_LEVEL_HIGH 0>;
		interrupt-names = "irq_jpege2";
		clocks = <&cru ACLK_JPEG_ENCODER2>, <&cru HCLK_JPEG_ENCODER2>;
		clock-names = "aclk_vcodec", "hclk_vcodec";
		rockchip,normal-rates = <594000000>, <0>;
		assigned-clocks = <&cru ACLK_JPEG_ENCODER2>;
		assigned-clock-rates = <594000000>;
		resets = <&cru SRST_A_JPEG_ENCODER2>, <&cru SRST_H_JPEG_ENCODER2>;
		reset-names = "video_a", "video_h";
		rockchip,skip-pmu-idle-request;
		rockchip,disable-auto-freq;
		iommus = <&jpege2_mmu>;
		rockchip,srv = <&mpp_srv>;
		rockchip,taskqueue-node = <2>;
		rockchip,ccu = <&jpege_ccu>;
		power-domains = <&power RK3588_PD_VDPU>;
		status = "disabled";
	};

	jpege2_mmu: iommu@fdba8800 {
		compatible = "rockchip,rk3588-iommu", "rockchip,rk3568-iommu", "rockchip,iommu-v2";
		reg = <0x0 0xfdba8800 0x0 0x40>;
		interrupts = <GIC_SPI 125 IRQ_TYPE_LEVEL_HIGH 0>;
		interrupt-names = "irq_jpege2_mmu";
		clocks = <&cru ACLK_JPEG_ENCODER2>, <&cru HCLK_JPEG_ENCODER2>;
		clock-names = "aclk", "iface";
		power-domains = <&power RK3588_PD_VDPU>;
		#iommu-cells = <0>;
		status = "disabled";
	};

	jpege3: jpege-core@fdbac000 {
		compatible = "rockchip,vpu-jpege-core";
		reg = <0x0 0xfdbac000 0x0 0x400>;
		interrupts = <GIC_SPI 128 IRQ_TYPE_LEVEL_HIGH 0>;
		interrupt-names = "irq_jpege3";
		clocks = <&cru ACLK_JPEG_ENCODER3>, <&cru HCLK_JPEG_ENCODER3>;
		clock-names = "aclk_vcodec", "hclk_vcodec";
		rockchip,normal-rates = <594000000>, <0>;
		assigned-clocks = <&cru ACLK_JPEG_ENCODER3>;
		assigned-clock-rates = <594000000>;
		resets = <&cru SRST_A_JPEG_ENCODER3>, <&cru SRST_H_JPEG_ENCODER3>;
		reset-names = "video_a", "video_h";
		rockchip,skip-pmu-idle-request;
		rockchip,disable-auto-freq;
		iommus = <&jpege3_mmu>;
		rockchip,srv = <&mpp_srv>;
		rockchip,taskqueue-node = <2>;
		rockchip,ccu = <&jpege_ccu>;
		power-domains = <&power RK3588_PD_VDPU>;
		status = "disabled";
	};

	jpege3_mmu: iommu@fdbac800 {
		compatible = "rockchip,rk3588-iommu", "rockchip,rk3568-iommu", "rockchip,iommu-v2";
		reg = <0x0 0xfdbac800 0x0 0x40>;
		interrupts = <GIC_SPI 127 IRQ_TYPE_LEVEL_HIGH 0>;
		interrupt-names = "irq_jpege3_mmu";
		clocks = <&cru ACLK_JPEG_ENCODER3>, <&cru HCLK_JPEG_ENCODER3>;
		clock-names = "aclk", "iface";
		power-domains = <&power RK3588_PD_VDPU>;
		#iommu-cells = <0>;
		status = "disabled";
	};

	iep: iep@fdbb0000 {
		compatible = "rockchip,iep-v2";
		reg = <0x0 0xfdbb0000 0x0 0x500>;
		interrupts = <GIC_SPI 117 IRQ_TYPE_LEVEL_HIGH 0>;
		interrupt-names = "irq_iep";
		clocks = <&cru ACLK_IEP2P0>, <&cru HCLK_IEP2P0>, <&cru CLK_IEP2P0_CORE>;
		clock-names = "aclk", "hclk", "sclk";
		rockchip,normal-rates = <594000000>, <0>;
		assigned-clocks = <&cru ACLK_IEP2P0>;
		assigned-clock-rates = <594000000>;
		resets = <&cru SRST_A_IEP2P0>, <&cru SRST_H_IEP2P0>, <&cru SRST_IEP2P0_CORE>;
		reset-names = "rst_a", "rst_h", "rst_s";
		rockchip,skip-pmu-idle-request;
		rockchip,disable-auto-freq;
		power-domains = <&power RK3588_PD_VDPU>;
		rockchip,srv = <&mpp_srv>;
		rockchip,taskqueue-node = <6>;
		iommus = <&iep_mmu>;
		status = "disabled";
	};

	iep_mmu: iommu@fdbb0800 {
		compatible = "rockchip,rk3588-iommu", "rockchip,rk3568-iommu", "rockchip,iommu-v2";
		reg = <0x0 0xfdbb0800 0x0 0x100>;
		interrupts = <GIC_SPI 117 IRQ_TYPE_LEVEL_HIGH 0>;
		interrupt-names = "irq_iep_mmu";
		clocks = <&cru ACLK_IEP2P0>, <&cru HCLK_IEP2P0>;
		clock-names = "aclk", "iface";
		#iommu-cells = <0>;
		power-domains = <&power RK3588_PD_VDPU>;
		status = "disabled";
	};

	rkvenc_ccu: rkvenc-ccu {
		compatible = "rockchip,rkv-encoder-v2-ccu";
		status = "disabled";
	};

	rkvenc0: rkvenc-core@fdbd0000 {
		compatible = "rockchip,rkv-encoder-v2-core";
		reg = <0x0 0xfdbd0000 0x0 0x6000>;
		interrupts = <GIC_SPI 101 IRQ_TYPE_LEVEL_HIGH 0>;
		interrupt-names = "irq_rkvenc0";
		clocks = <&cru ACLK_RKVENC0>, <&cru HCLK_RKVENC0>, <&cru CLK_RKVENC0_CORE>;
		clock-names = "aclk_vcodec", "hclk_vcodec", "clk_core";
		rockchip,normal-rates = <500000000>, <0>, <800000000>;
		assigned-clocks = <&cru ACLK_RKVENC0>, <&cru CLK_RKVENC0_CORE>;
		assigned-clock-rates = <500000000>, <800000000>;
		resets = <&cru SRST_A_RKVENC0>, <&cru SRST_H_RKVENC0>, <&cru SRST_RKVENC0_CORE>;
		reset-names = "video_a", "video_h", "video_core";
		rockchip,skip-pmu-idle-request;
		iommus = <&rkvenc0_mmu>;
		rockchip,srv = <&mpp_srv>;
		rockchip,ccu = <&rkvenc_ccu>;
		rockchip,taskqueue-node = <7>;
		rockchip,task-capacity = <8>;
		power-domains = <&power RK3588_PD_VENC0>;
		//operating-points-v2 = <&venc_opp_table>;
		status = "disabled";
	};

	rkvenc0_mmu: iommu@fdbdf000 {
		compatible = "rockchip,rk3588-iommu", "rockchip,rk3568-iommu", "rockchip,iommu-v2";
		reg = <0x0 0xfdbdf000 0x0 0x40>, <0x0 0xfdbdf040 0x0 0x40>;
		interrupts = <GIC_SPI 99 IRQ_TYPE_LEVEL_HIGH 0>,
			     <GIC_SPI 100 IRQ_TYPE_LEVEL_HIGH 0>;
		interrupt-names = "irq_rkvenc0_mmu0", "irq_rkvenc0_mmu1";
		clocks = <&cru ACLK_RKVENC0>, <&cru HCLK_RKVENC0>;
		clock-names = "aclk", "iface";
		rockchip,disable-mmu-reset;
		rockchip,enable-cmd-retry;
		rockchip,shootdown-entire;
		#iommu-cells = <0>;
		power-domains = <&power RK3588_PD_VENC0>;
		status = "disabled";
	};

	rkvenc1: rkvenc-core@fdbe0000 {
		compatible = "rockchip,rkv-encoder-v2-core";
		reg = <0x0 0xfdbe0000 0x0 0x6000>;
		interrupts = <GIC_SPI 104 IRQ_TYPE_LEVEL_HIGH 0>;
		interrupt-names = "irq_rkvenc1";
		clocks = <&cru ACLK_RKVENC1>, <&cru HCLK_RKVENC1>, <&cru CLK_RKVENC1_CORE>;
		clock-names = "aclk_vcodec", "hclk_vcodec", "clk_core";
		rockchip,normal-rates = <500000000>, <0>, <800000000>;
		assigned-clocks = <&cru ACLK_RKVENC1>, <&cru CLK_RKVENC1_CORE>;
		assigned-clock-rates = <500000000>, <800000000>;
		resets = <&cru SRST_A_RKVENC1>, <&cru SRST_H_RKVENC1>, <&cru SRST_RKVENC1_CORE>;
		reset-names = "video_a", "video_h", "video_core";
		rockchip,skip-pmu-idle-request;
		iommus = <&rkvenc1_mmu>;
		rockchip,srv = <&mpp_srv>;
		rockchip,ccu = <&rkvenc_ccu>;
		rockchip,taskqueue-node = <7>;
		rockchip,task-capacity = <8>;
		power-domains = <&power RK3588_PD_VENC1>;
		//operating-points-v2 = <&venc_opp_table>;
		status = "disabled";
	};

	rkvenc1_mmu: iommu@fdbef000 {
		compatible = "rockchip,rk3588-iommu", "rockchip,rk3568-iommu", "rockchip,iommu-v2";
		reg = <0x0 0xfdbef000 0x0 0x40>, <0x0 0xfdbef040 0x0 0x40>;
		interrupts = <GIC_SPI 102 IRQ_TYPE_LEVEL_HIGH 0>,
			     <GIC_SPI 103 IRQ_TYPE_LEVEL_HIGH 0>;
		interrupt-names = "irq_rkvenc1_mmu0", "irq_rkvenc1_mmu1";
		clocks = <&cru ACLK_RKVENC1>, <&cru HCLK_RKVENC1>;
		lock-names = "aclk", "iface";
		rockchip,disable-mmu-reset;
		rockchip,enable-cmd-retry;
		rockchip,shootdown-entire;
		#iommu-cells = <0>;
		power-domains = <&power RK3588_PD_VENC1>;
		status = "disabled";
	};

	venc_opp_table: venc-opp-table {
		compatible = "operating-points-v2";

		nvmem-cells = <&codec_leakage>, <&venc_opp_info>;
		nvmem-cell-names = "leakage", "opp-info";
		rockchip,leakage-voltage-sel = <
			1	15	0
			16	25	1
			26	254	2
		>;

		rockchip,grf = <&sys_grf>;
		volt-mem-read-margin = <
			855000	1
			765000	2
			675000	3
			495000	4
		>;

		opp-800000000 {
			opp-hz = /bits/ 64 <800000000>;
			opp-microvolt = <750000 750000 850000>,
					<750000 750000 850000>;
			opp-microvolt-L0 = <800000 800000 850000>,
					   <800000 800000 850000>;
			opp-microvolt-L1 = <775000 775000 850000>,
					   <775000 775000 850000>;
			opp-microvolt-L2 = <750000 750000 850000>,
					   <750000 750000 850000>;
		};
	};

	rkvdec_ccu: rkvdec-ccu@fdc30000 {
		compatible = "rockchip,rkv-decoder-v2-ccu";
		reg = <0x0 0xfdc30000 0x0 0x100>;
		reg-names = "ccu";
		clocks = <&cru ACLK_RKVDEC_CCU>;
		clock-names = "aclk_ccu";
		assigned-clocks = <&cru ACLK_RKVDEC_CCU>;
		assigned-clock-rates = <600000000>;
		resets = <&cru SRST_A_RKVDEC_CCU>;
		reset-names = "video_ccu";
		rockchip,skip-pmu-idle-request;
		/* 1: soft ccu 2: hw ccu */
		rockchip,ccu-mode = <1>;
		power-domains = <&power RK3588_PD_RKVDEC0>;
		status = "disabled";
	};

	rkvdec0: rkvdec-core@fdc38000 {
		compatible = "rockchip,rkv-decoder-v2";
		reg = <0x0 0xfdc38100 0x0 0x400>, <0x0 0xfdc38000 0x0 0x100>;
		reg-names = "regs", "link";
		interrupts = <GIC_SPI 95 IRQ_TYPE_LEVEL_HIGH 0>;
		interrupt-names = "irq_rkvdec0";
		clocks = <&cru ACLK_RKVDEC0>, <&cru HCLK_RKVDEC0>, <&cru CLK_RKVDEC0_CORE>,
			 <&cru CLK_RKVDEC0_CA>, <&cru CLK_RKVDEC0_HEVC_CA>;
		clock-names = "aclk_vcodec", "hclk_vcodec", "clk_core",
			      "clk_cabac", "clk_hevc_cabac";
		rockchip,normal-rates = <800000000>, <0>, <600000000>,
					<600000000>, <1000000000>;
		assigned-clocks = <&cru ACLK_RKVDEC0>, <&cru CLK_RKVDEC0_CORE>,
				  <&cru CLK_RKVDEC0_CA>, <&cru CLK_RKVDEC0_HEVC_CA>;
		assigned-clock-rates = <800000000>, <600000000>,
				       <600000000>, <1000000000>;
		resets = <&cru SRST_A_RKVDEC0>, <&cru SRST_H_RKVDEC0>, <&cru SRST_RKVDEC0_CORE>,
			 <&cru SRST_RKVDEC0_CA>, <&cru SRST_RKVDEC0_HEVC_CA>;
		reset-names = "video_a", "video_h", "video_core",
			      "video_cabac", "video_hevc_cabac";
		rockchip,skip-pmu-idle-request;
		iommus = <&rkvdec0_mmu>;
		rockchip,srv = <&mpp_srv>;
		rockchip,ccu = <&rkvdec_ccu>;
		rockchip,core-mask = <0x00010001>;
		rockchip,task-capacity = <16>;
		rockchip,taskqueue-node = <9>;
		rockchip,sram = <&rkvdec0_sram>;
		/* rcb_iova: start and size 1M@4095M */
		rockchip,rcb-iova = <0xFFF00000 0x100000>;
		rockchip,rcb-info = <136 24576>, <137 49152>, <141 90112>, <140 49152>,
				    <139 180224>, <133 49152>, <134 8192>, <135 4352>,
				    <138 13056>, <142 291584>;
		rockchip,rcb-min-width = <512>;
		power-domains = <&power RK3588_PD_RKVDEC0>;
		status = "disabled";
	};

	rkvdec0_mmu: iommu@fdc38700 {
		compatible = "rockchip,rk3588-iommu", "rockchip,rk3568-iommu", "rockchip,iommu-v2";
		reg = <0x0 0xfdc38700 0x0 0x40>, <0x0 0xfdc38740 0x0 0x40>;
		interrupts = <GIC_SPI 96 IRQ_TYPE_LEVEL_HIGH 0>;
		interrupt-names = "irq_rkvdec0_mmu";
		clocks = <&cru ACLK_RKVDEC0>, <&cru HCLK_RKVDEC0>;
		clock-names = "aclk", "iface";
		rockchip,disable-mmu-reset;
		rockchip,enable-cmd-retry;
		rockchip,shootdown-entire;
		rockchip,master-handle-irq;
		#iommu-cells = <0>;
		power-domains = <&power RK3588_PD_RKVDEC0>;
		status = "disabled";
	};

	rkvdec1: rkvdec-core@fdc48000 {
		compatible = "rockchip,rkv-decoder-v2";
		reg = <0x0 0xfdc48100 0x0 0x400>, <0x0 0xfdc48000 0x0 0x100>;
		reg-names = "regs", "link";
		interrupts = <GIC_SPI 97 IRQ_TYPE_LEVEL_HIGH 0>;
		interrupt-names = "irq_rkvdec1";
		clocks = <&cru ACLK_RKVDEC1>, <&cru HCLK_RKVDEC1>, <&cru CLK_RKVDEC1_CORE>,
			 <&cru CLK_RKVDEC1_CA>, <&cru CLK_RKVDEC1_HEVC_CA>;
		clock-names = "aclk_vcodec", "hclk_vcodec", "clk_core",
			      "clk_cabac", "clk_hevc_cabac";
		rockchip,normal-rates = <800000000>, <0>, <600000000>,
					<600000000>, <1000000000>;
		assigned-clocks = <&cru ACLK_RKVDEC1>, <&cru CLK_RKVDEC1_CORE>,
				  <&cru CLK_RKVDEC1_CA>, <&cru CLK_RKVDEC1_HEVC_CA>;
		assigned-clock-rates = <800000000>, <600000000>,
				       <600000000>, <1000000000>;
		resets = <&cru SRST_A_RKVDEC1>, <&cru SRST_H_RKVDEC1>, <&cru SRST_RKVDEC1_CORE>,
			 <&cru SRST_RKVDEC1_CA>, <&cru SRST_RKVDEC1_HEVC_CA>;
		reset-names = "video_a", "video_h", "video_core",
			      "video_cabac", "video_hevc_cabac";
		rockchip,skip-pmu-idle-request;
		iommus = <&rkvdec1_mmu>;
		rockchip,srv = <&mpp_srv>;
		rockchip,ccu = <&rkvdec_ccu>;
		rockchip,core-mask = <0x00020002>;
		rockchip,task-capacity = <16>;
		rockchip,taskqueue-node = <9>;
		rockchip,sram = <&rkvdec1_sram>;
		/* rcb_iova: start and size 1M@4094M */
		rockchip,rcb-iova = <0xFFE00000 0x100000>;
		rockchip,rcb-info = <136 24576>, <137 49152>, <141 90112>, <140 49152>,
				    <139 180224>, <133 49152>, <134 8192>, <135 4352>,
				    <138 13056>, <142 291584>;
		rockchip,rcb-min-width = <512>;
		power-domains = <&power RK3588_PD_RKVDEC1>;
		status = "disabled";
	};

	rkvdec1_mmu: iommu@fdc48700 {
		compatible = "rockchip,rk3588-iommu", "rockchip,rk3568-iommu", "rockchip,iommu-v2";
		reg = <0x0 0xfdc48700 0x0 0x40>, <0x0 0xfdc48740 0x0 0x40>;
		interrupts = <GIC_SPI 98 IRQ_TYPE_LEVEL_HIGH 0>;
		interrupt-names = "irq_rkvdec1_mmu";
		clocks = <&cru ACLK_RKVDEC1>, <&cru HCLK_RKVDEC1>;
		clock-names = "aclk", "iface";
		rockchip,disable-mmu-reset;
		rockchip,enable-cmd-retry;
		rockchip,shootdown-entire;
		rockchip,master-handle-irq;
		#iommu-cells = <0>;
		power-domains = <&power RK3588_PD_RKVDEC1>;
		status = "disabled";
	};

	av1d: av1d@fdc70000 {
		compatible = "rockchip,av1-decoder";
		reg = <0x0 0xfdc70000 0x0 0x800>,  <0x0 0xfdc80000 0x0 0x400>,
		      <0x0 0xfdc90000 0x0 0x400>;
		reg-names = "vcd", "cache", "afbc";
		interrupts = <GIC_SPI 108 IRQ_TYPE_LEVEL_HIGH 0>, <GIC_SPI 107 IRQ_TYPE_LEVEL_HIGH 0>,
			     <GIC_SPI 106 IRQ_TYPE_LEVEL_HIGH 0>;
		interrupt-names = "irq_av1d", "irq_cache", "irq_afbc";
		clocks = <&cru ACLK_AV1>, <&cru PCLK_AV1>;
		clock-names = "aclk_vcodec", "hclk_vcodec";
		rockchip,normal-rates = <400000000>, <400000000>;
		assigned-clocks = <&cru ACLK_AV1>, <&cru PCLK_AV1>;
		assigned-clock-rates = <400000000>, <400000000>;
		resets = <&cru SRST_A_AV1>, <&cru SRST_P_AV1>;
		reset-names = "video_a", "video_h";
		iommus = <&av1d_mmu>;
		rockchip,srv = <&mpp_srv>;
		rockchip,taskqueue-node = <11>;
		power-domains = <&power RK3588_PD_AV1>;
		status = "disabled";
	};

	av1d_mmu: iommu@fdca0000 {
		compatible = "rockchip,iommu-av1d";
		reg = <0x0 0xfdca0000 0x0 0x600>;
		interrupts = <GIC_SPI 109 IRQ_TYPE_LEVEL_HIGH 0>;
		interrupt-names = "irq_av1d_mmu";
		clocks = <&cru ACLK_AV1>, <&cru PCLK_AV1>;
		clock-names = "aclk", "iface";
		#iommu-cells = <0>;
		power-domains = <&power RK3588_PD_AV1>;
		status = "disabled";
	};
};

&otp {
	specification_serial_number: specification-serial-number@6 {
		reg = <0x06 0x1>;
		bits = <0 5>;
	};

	customer_demand: customer-demand@22 {
		reg = <0x22 0x1>;
		bits = <4 4>;
	};

	npu_opp_info: npu-opp-info@55 {
		reg = <0x55 0x6>;
	};

	gpu_opp_info: gpu-opp-info@4f {
		reg = <0x4f 0x6>;
	};

	venc_opp_info: venc-opp-info@67 {
		reg = <0x67 0x6>;
	};
};

&system_sram2 {
	/* start address and size should be 4k algin */
	rkvdec0_sram: rkvdec-sram@0 {
		reg = <0x0 0x78000>;
	};
	rkvdec1_sram: rkvdec-sram@78000 {
		reg = <0x78000 0x77000>;
	};
};

&crypto {
	status = "okay";
};

&rng {
	status = "okay";
};

&av1d {
	status = "okay";
};

&av1d_mmu {
	status = "okay";
};


&jpegd {
	status = "okay";
};

&jpegd_mmu {
	status = "okay";
};

&jpege_ccu {
	status = "okay";
};

&jpege0 {
	status = "okay";
};

&jpege0_mmu {
	status = "okay";
};

&jpege1 {
	status = "okay";
};

&jpege1_mmu {
	status = "okay";
};

&jpege2 {
	status = "okay";
};

&jpege2_mmu {
	status = "okay";
};

&jpege3 {
	status = "okay";
};

&jpege3_mmu {
	status = "okay";
};

&mpp_srv {
	status = "okay";
};

&rga3_core0 {
	status = "okay";
};

&rga3_0_mmu {
	status = "okay";
};

&rga3_core1 {
	status = "okay";
};

&rga3_1_mmu {
	status = "okay";
};

&rga2 {
	status = "okay";
};

&rkvdec_ccu {
	status = "okay";
};

&rkvdec0 {
	status = "okay";
};

&rkvdec0_mmu {
	status = "okay";
};

&rkvdec1 {
	status = "okay";
};

&rkvdec1_mmu {
	status = "okay";
};

&vdpu {
	status = "okay";
};

&vdpu_mmu {
	status = "okay";
};

&rknpu {
	status = "okay";
};
